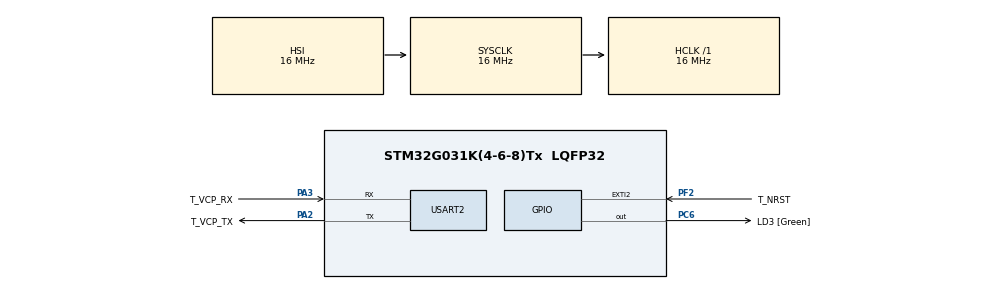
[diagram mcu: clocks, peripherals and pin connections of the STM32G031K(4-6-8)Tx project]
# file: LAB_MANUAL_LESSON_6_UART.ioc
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Mcu.Family=STM32G0
Mcu.Name=STM32G031K(4-6-8)Tx
Mcu.Package=LQFP32
NVIC.EXTI2_3_IRQn=true\:0\:0\:false\:false\:true\:true\:true
NVIC.USART2_IRQn=true\:0\:0\:false\:false\:true\:true\:true
PA13.GPIO_Label=T_JTMS
PA13.Mode=Serial_Wire
PA13.Signal=SYS_SWDIO
PA14-BOOT0.GPIO_Label=T_JTCK
PA14-BOOT0.Mode=Serial_Wire
PA14-BOOT0.Signal=SYS_SWCLK
PA2.GPIO_Label=T_VCP_TX
PA2.Mode=Asynchronous
PA2.Signal=USART2_TX
PA3.GPIO_Label=T_VCP_RX
PA3.Mode=Asynchronous
PA3.Signal=USART2_RX
PC14-OSC32_IN\ (PC14).Mode=LSE-External-Oscillator
PC14-OSC32_IN\ (PC14).Signal=RCC_OSC32_IN
PC15-OSC32_OUT\ (PC15).Mode=LSE-External-Oscillator
PC15-OSC32_OUT\ (PC15).Signal=RCC_OSC32_OUT
PC6.GPIO_Label=LD3 [Green]
PC6.Signal=GPIO_Output
PF2\ -\ NRST.GPIO_Label=T_NRST
PF2\ -\ NRST.GPIO_ModeDefaultEXTI=GPIO_MODE_IT_FALLING
PF2\ -\ NRST.GPIO_PuPd=GPIO_PULLUP
PF2\ -\ NRST.Signal=GPXTI2
ProjectManager.HeapSize=0x200
ProjectManager.StackSize=0x400
ProjectManager.TargetToolchain=MDK-ARM V5
RCC.AHBFreq_Value=16000000
RCC.CortexFreq_Value=16000000
RCC.EXTERNAL_CLOCK_VALUE=12288000
RCC.HCLKFreq_Value=16000000
RCC.HSE_VALUE=8000000
RCC.HSI_VALUE=16000000
RCC.SYSCLKFreq_VALUE=16000000
RCC.VCOOutputFreq_Value=128000000
USART2.VirtualMode-Asynchronous=VM_ASYNC
board=NUCLEO-G031K8

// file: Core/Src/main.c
/* USER CODE BEGIN Header */
/**
  ******************************************************************************
  * @file           : main.c
  * @brief          : Main program body
  ******************************************************************************
  * @attention
  *
  * <h2><center>&copy; Copyright (c) 2020 STMicroelectronics.
  * All rights reserved.</center></h2>
  *
  * This software component is licensed by ST under BSD 3-Clause license,
  * the "License"; You may not use this file except in compliance with the
  * License. You may obtain a copy of the License at:
  *                        opensource.org/licenses/BSD-3-Clause
  *
  ******************************************************************************
  */
/* USER CODE END Header */

#include "main.h"
#include "usart.h"
#include "gpio.h"

void SystemClock_Config(void);

int main(void)
{

  /* MCU Configuration--------------------------------------------------------*/

  /* Reset of all peripherals, Initializes the Flash interface and the Systick. */
  HAL_Init();

  /* Configure the system clock */
  SystemClock_Config();

  /* Initialize all configured peripherals */
  MX_GPIO_Init();
  MX_USART2_UART_Init();
  /* USER CODE BEGIN 2 */
	printf("This is Test for Uart\r\n");
  /* USER CODE END 2 */

  /* Infinite loop */
  while (1)
  {

  }
}

void SystemClock_Config(void)
{
  RCC_OscInitTypeDef RCC_OscInitStruct = {0};
  RCC_ClkInitTypeDef RCC_ClkInitStruct = {0};

  /** Configure the main internal regulator output voltage
  */
  HAL_PWREx_ControlVoltageScaling(PWR_REGULATOR_VOLTAGE_SCALE1);
  /** Initializes the CPU, AHB and APB busses clocks
  */
  RCC_OscInitStruct.OscillatorType = RCC_OSCILLATORTYPE_HSI;
  RCC_OscInitStruct.HSIState = RCC_HSI_ON;
  RCC_OscInitStruct.HSIDiv = RCC_HSI_DIV1;
  RCC_OscInitStruct.HSICalibrationValue = RCC_HSICALIBRATION_DEFAULT;
  RCC_OscInitStruct.PLL.PLLState = RCC_PLL_NONE;
  if (HAL_RCC_OscConfig(&RCC_OscInitStruct) != HAL_OK)
  {
    Error_Handler();
  }
  /** Initializes the CPU, AHB and APB busses clocks
  */
  RCC_ClkInitStruct.ClockType = RCC_CLOCKTYPE_HCLK|RCC_CLOCKTYPE_SYSCLK
                              |RCC_CLOCKTYPE_PCLK1;
  RCC_ClkInitStruct.SYSCLKSource = RCC_SYSCLKSOURCE_HSI;
  RCC_ClkInitStruct.AHBCLKDivider = RCC_SYSCLK_DIV1;
  RCC_ClkInitStruct.APB1CLKDivider = RCC_HCLK_DIV1;

  if (HAL_RCC_ClockConfig(&RCC_ClkInitStruct, FLASH_LATENCY_0) != HAL_OK)
  {
    Error_Handler();
  }
}

/* USER CODE BEGIN 4 */
void HAL_GPIO_EXTI_Falling_Callback(uint16_t GPIO_Pin)
{
	printf("This is RST PIN \r\n");
}
/* USER CODE END 4 */

void Error_Handler(void)
{
}

/************************ (C) COPYRIGHT STMicroelectronics *****END OF FILE****/
